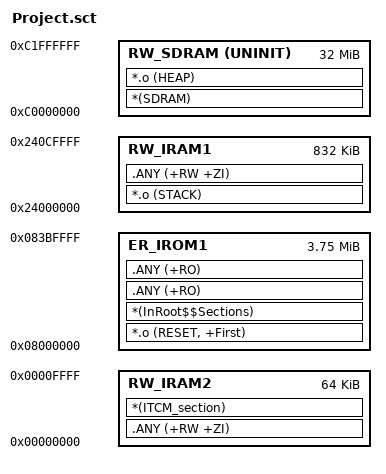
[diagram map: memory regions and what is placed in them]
; *************************************************************
; *** Scatter-Loading Description File generated by uVision ***
; *************************************************************

LR_IROM1 0x08000000 0x003C0000  {    ; load region size_region
  ER_IROM1 0x08000000 0x003C0000  {  ; load address = execution address
   *.o (RESET, +First)
   *(InRoot$$Sections)
   .ANY (+RO)
  .ANY (+RO)
  }
  RW_IRAM1 0x24000000 0x000D0000  {  ; RW data
    *.o (STACK)
   .ANY (+RW +ZI)
  }
  RW_IRAM2 0x00000000 0x00010000  {
   .ANY (+RW +ZI)
   *(ITCM_section)
  }

  RW_SDRAM 0xC0000000 UNINIT 0x2000000  {  ; SDRAM 32MB
    *(SDRAM)
	*.o (HEAP)
  }
}

